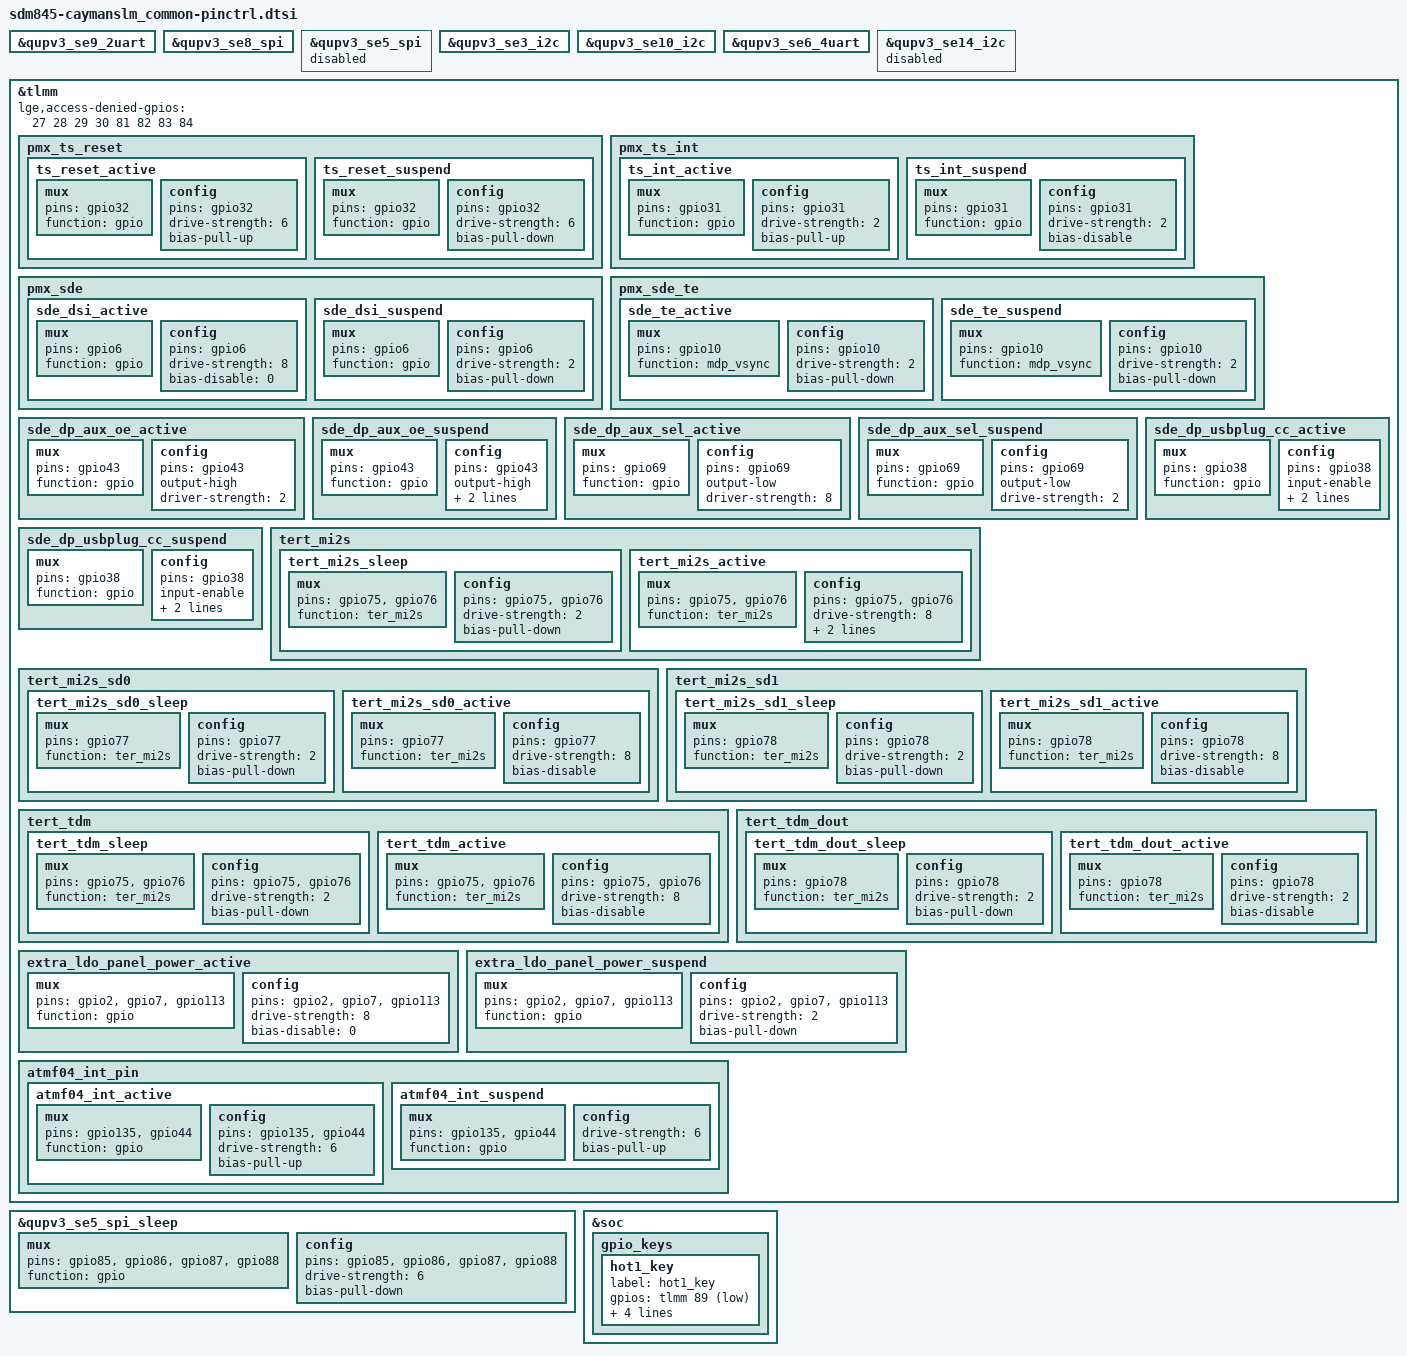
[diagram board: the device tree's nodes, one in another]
/* Copyright (c) 2017, The Linux Foundation. All rights reserved.
 *
 * This program is free software; you can redistribute it and/or modify
 * it under the terms of the GNU General Public License version 2 and
 * only version 2 as published by the Free Software Foundation.
 *
 * This program is distributed in the hope that it will be useful,
 * but WITHOUT ANY WARRANTY; without even the implied warranty of
 * MERCHANTABILITY or FITNESS FOR A PARTICULAR PURPOSE.  See the
 * GNU General Public License for more details.
 */


&qupv3_se9_2uart {
	status = "ok";
};

&qupv3_se8_spi {
	status = "ok";
};

&qupv3_se5_spi {
	status = "disable";
};

&qupv3_se3_i2c {
	status = "ok";
};

&qupv3_se10_i2c {
	status = "ok";
};

&qupv3_se6_4uart {
	status = "ok";
};

&qupv3_se14_i2c {
	status = "disable";
};

/* Fix not to redefine TLMM*/
/*
&soc {
	tlmm: pinctrl@03400000 {
		      compatible = "qcom,sdm845-pinctrl";
		      reg = <0x03400000 0xc00000>;
		      interrupts = <0 208 0>;
		      gpio-controller;
		      #gpio-cells = <2>;
		      interrupt-controller;
		      #interrupt-cells = <2>;
*/
&tlmm {
		lge,access-denied-gpios = <27 28 29 30 81 82 83 84>;

		pmx_ts_reset {
			ts_reset_active: ts_reset_active {
				mux {
					pins = "gpio32";
					function = "gpio";
				};
				config {
					pins = "gpio32";
					drive-strength = <6>;
					bias-pull-up;
				};
			};

			ts_reset_suspend: ts_reset_suspend {
				mux {
					pins = "gpio32";
					function = "gpio";
				};
				config {
					pins = "gpio32";
					drive-strength = <6>;
					bias-pull-down;
				};
			};
		};

		pmx_ts_int {
			ts_int_active: ts_int_active {
				mux {
					pins = "gpio31";
					function = "gpio";
				};
				config {
					pins = "gpio31";
					drive-strength = <2>;
					bias-pull-up;
				};
		};

			ts_int_suspend: ts_int_suspend {
				mux {
					pins = "gpio31";
					function = "gpio";
				};
				config {
					pins = "gpio31";
					drive-strength = <2>;
					bias-disable;
				};
			};
		};

		pmx_sde: pmx_sde {
			sde_dsi_active: sde_dsi_active {
				mux {
					pins = "gpio6";
					function = "gpio";
				};

				config {
					pins = "gpio6";
					drive-strength = <8>;   /* 8 mA */
					bias-disable = <0>;   /* no pull */
				};
			};
			sde_dsi_suspend: sde_dsi_suspend {
				mux {
					pins = "gpio6";
					function = "gpio";
				};

				config {
					pins = "gpio6";
					drive-strength = <2>;   /* 2 mA */
					bias-pull-down;         /* PULL DOWN */
				};
			};
		};

		pmx_sde_te {
			sde_te_active: sde_te_active {
				mux {
					pins = "gpio10";
					function = "mdp_vsync";
				};

				config {
					pins = "gpio10";
					drive-strength = <2>;   /* 2 mA */
					bias-pull-down;         /* PULL DOWN */
				};
			};

			sde_te_suspend: sde_te_suspend {
				mux {
					pins = "gpio10";
					function = "mdp_vsync";
				};

				config {
					pins = "gpio10";
					drive-strength = <2>;   /* 2 mA */
					bias-pull-down;         /* PULL DOWN */
				};
			};
		};

		sde_dp_aux_oe_active:sde_dp_aux_oe_active {
			mux {
				pins = "gpio43";
				function = "gpio";
			};

			config {
				pins = "gpio43";
				output-high;
				driver-strength = <2>; /* 2mA */
			};
		};

		sde_dp_aux_oe_suspend:sde_dp_aux_oe_suspend {
			mux {
				pins = "gpio43";
				function = "gpio";
			};

			config {
				pins = "gpio43";
				output-high;
				bias-pull-up;
				driver-strength = <8>;
			};
		};

		sde_dp_aux_sel_active:sde_dp_aux_sel_active {
			mux {
				pins = "gpio69";
				function = "gpio";
			};

			config {
				pins = "gpio69";
				output-low;
				driver-strength = <8>;
			};
		};

		sde_dp_aux_sel_suspend:sde_dp_aux_sel_suspend {
			mux {
				pins = "gpio69";
				function = "gpio";
			};

			config {
				pins = "gpio69";
				output-low;
				drive-strength = <2>;
			};
		};

		sde_dp_usbplug_cc_active:sde_dp_usbplug_cc_active {
			mux {
				pins = "gpio38";
				function = "gpio";
			};

			config {
				pins = "gpio38";
				input-enable;
				bias-pull-down;
				driver-strength = <16>;
			};
		};

		sde_dp_usbplug_cc_suspend:sde_dp_usbplug_cc_suspend {
			mux {
				pins = "gpio38";
				function = "gpio";
			};

			config {
				pins = "gpio38";
				input-enable;
				bias-pull-down;
				driver-strength = <2>;
			};
		};

		tert_mi2s {
			tert_mi2s_sleep: tert_mi2s_sleep {
				mux {
						pins = "gpio75", "gpio76";
						function = "ter_mi2s";
					};

				config {
						pins = "gpio75", "gpio76";
						drive-strength = <2>;   /* 2 mA */
						bias-pull-down;         /* PULL DOWN */
				};
			};

			tert_mi2s_active: tert_mi2s_active {
				mux {
					pins = "gpio75", "gpio76";
					function = "ter_mi2s";
				};

				config {
					pins = "gpio75", "gpio76";
					drive-strength = <8>;   /* 8 mA */
					bias-disable;           /* NO PULL */
					output-high;
				};
			};
		};

		tert_mi2s_sd0 {
			tert_mi2s_sd0_sleep: tert_mi2s_sd0_sleep {
                    mux {
                         pins = "gpio77";
                         function = "ter_mi2s";
                      };

                    config {
                         pins = "gpio77";
                         drive-strength = <2>;   /* 2 mA */
                         bias-pull-down;         /* PULL DOWN */
                    };
              };

			tert_mi2s_sd0_active: tert_mi2s_sd0_active {
                    mux {
                         pins = "gpio77";
                         function = "ter_mi2s";
                    };

                    config {
                          pins = "gpio77";
                          drive-strength = <8>;   /* 8 mA */
                          bias-disable;           /* NO PULL */
                      };
                 };
		};

		tert_mi2s_sd1 {
			tert_mi2s_sd1_sleep: tert_mi2s_sd1_sleep {
                    mux {
                         pins = "gpio78";
                         function = "ter_mi2s";
                    };

                    config {
                           pins = "gpio78";
                           drive-strength = <2>;   /* 2 mA */
                           bias-pull-down;         /* PULL DOWN */
                        };
                  };

			tert_mi2s_sd1_active: tert_mi2s_sd1_active {
                     mux {
					       pins = "gpio78";
                           function = "ter_mi2s";
					};

                    config {
                            pins = "gpio78";
                            drive-strength = <8>;   /* 8 mA */
                            bias-disable;           /* NO PULL */
						  };
                  };
		};

		tert_tdm {
			tert_tdm_sleep: tert_tdm_sleep {
					mux {
						pins = "gpio75", "gpio76";
						function = "ter_mi2s";
					};
					config {
						pins = "gpio75", "gpio76";
						drive-strength = <2>;   /* 2 mA */
						bias-pull-down;         /* PULL DOWN */
					};
				};
			tert_tdm_active: tert_tdm_active {
					 mux {
						 pins = "gpio75", "gpio76";
						 function = "ter_mi2s";
					 };
					 config {
						 pins = "gpio75", "gpio76";
						 //drive-strength = <2>;  bias-disable;
						 //drive-strength = <2>;  bias-pull-up
						 //drive-strength = <2>;  bias-pull-down
						 drive-strength = <8>; bias-disable;
						 //input-enable;
					};
				};
		};

		tert_tdm_dout {
			tert_tdm_dout_sleep: tert_tdm_dout_sleep {
				mux {
						pins = "gpio78";
						function = "ter_mi2s";
					};
				config {
							pins = "gpio78";
							drive-strength = <2>;   /* 2 mA */
							bias-pull-down;         /* PULL DOWN */
					};
				};
			tert_tdm_dout_active: tert_tdm_dout_active {
				mux {
						pins = "gpio78";
						function = "ter_mi2s";
					};
				config {
						pins = "gpio78";
						drive-strength = <2>;   /* 2 mA */
						bias-disable;           /* NO PULL */
						//output-high;
					};
				};
		};
//	};
};

&tlmm {
			extra_ldo_panel_power_active: extra_ldo_panel_power_active {
				mux {
					pins = "gpio2", "gpio7", "gpio113";
					function = "gpio";
				};

				config {
					pins = "gpio2", "gpio7", "gpio113";
					drive-strength = <8>;   /* 8 mA */
					bias-disable = <0>;   /* no pull */
				};

			};
			extra_ldo_panel_power_suspend: extra_ldo_panel_power_suspend {
				mux {
					pins = "gpio2", "gpio7", "gpio113";
					function = "gpio";
				};

				config {
					pins = "gpio2", "gpio7", "gpio113";
					drive-strength = <2>;   /* 2 mA */
					bias-pull-down;         /* PULL DOWN */
				};
			};

		atmf04_int_pin {
			atmf04_int_active: atmf04_int_active {
				mux {
					pins = "gpio135", "gpio44";
					function = "gpio";
				};
				config {
					pins = "gpio135", "gpio44";
					drive-strength = <6>;   /* 6 MA */
					bias-pull-up;           /* PULL UP*/
				};
			};

			atmf04_int_suspend: atmf04_int_suspend {
				mux {
					pins = "gpio135", "gpio44";
					function = "gpio";
				};
				config {
					drive-strength = <6>;   /* 6 MA */
					bias-pull-up;           /* PULL UP */
				};
			};
		};
};

&qupv3_se5_spi_sleep {
	mux {
		pins = "gpio85", "gpio86", "gpio87",
					"gpio88";
		function = "gpio";
	};

	config {
		pins = "gpio85", "gpio86", "gpio87",
					"gpio88";
		drive-strength = <6>;
		bias-pull-down;
	};
};

&soc {
	gpio_keys {
		hot1_key {
			label = "hot1_key";
			gpios = <&tlmm 89 GPIO_ACTIVE_LOW>;
			linux,input-type = <1>;
			linux,code = <377>;
			gpio-key,wakeup;
			debounce-interval = <15>;
		};
	};
};
